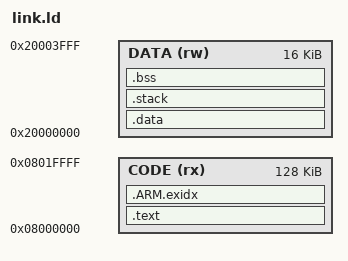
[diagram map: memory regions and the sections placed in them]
/*
 * Linker script for GD32F3x0 with GNU ld
 */

MEMORY
{
    CODE (rx) : ORIGIN = 0x08000000, LENGTH = 128k /* GD32F350RB: 128KB Flash */
    DATA (rw) : ORIGIN = 0x20000000, LENGTH =  16k /* GD32F350RB: 16KB SRAM */
}
ENTRY(Reset_Handler)
_system_stack_size = 0x400;

SECTIONS
{
    .text :
    {
        . = ALIGN(4);
        _stext = .;
        KEEP(*(.isr_vector))            /* Startup code */
        . = ALIGN(4);
        *(.text)
        *(.text.*)
        *(.rodata)
        *(.rodata*)
        *(.glue_7)
        *(.glue_7t)
        *(.gnu.linkonce.t*)

        . = ALIGN(4);
        __fsymtab_start = .;
        KEEP(*(FSymTab))
        __fsymtab_end = .;
        . = ALIGN(4);
        __vsymtab_start = .;
        KEEP(*(VSymTab))
        __vsymtab_end = .;
        . = ALIGN(4);

        . = ALIGN(4);
        __rt_init_start = .;
        KEEP(*(SORT(.rti_fn*)))
        __rt_init_end = .;
        . = ALIGN(4);

        . = ALIGN(4);
        _etext = .;
    } > CODE = 0

    __exidx_start = .;
    .ARM.exidx :
    {
        *(.ARM.exidx* .gnu.linkonce.armexidx.*)

        _sidata = .;
    } > CODE
    __exidx_end = .;

    .data : AT (_sidata)
    {
        . = ALIGN(4);
        _sdata = . ;

        *(.data)
        *(.data.*)
        *(.gnu.linkonce.d*)

        . = ALIGN(4);
        _edata = . ;
    } >DATA

    .stack : 
    {
        . = . + _system_stack_size;
        . = ALIGN(4);
        _estack = .;
    } >DATA

    __bss_start = .;
    .bss :
    {
        . = ALIGN(4);
        _sbss = .;

        *(.bss)
        *(.bss.*)
        *(COMMON)

        . = ALIGN(4);
        _ebss = . ;
        *(.bss.init)
    } > DATA
    __bss_end = .;

    _end = .;

    .stab          0 : { *(.stab) }
    .stabstr       0 : { *(.stabstr) }
    .stab.excl     0 : { *(.stab.excl) }
    .stab.exclstr  0 : { *(.stab.exclstr) }
    .stab.index    0 : { *(.stab.index) }
    .stab.indexstr 0 : { *(.stab.indexstr) }
    .comment       0 : { *(.comment) }

    .debug          0 : { *(.debug) }
    .line           0 : { *(.line) }
    .debug_srcinfo  0 : { *(.debug_srcinfo) }
    .debug_sfnames  0 : { *(.debug_sfnames) }
    .debug_aranges  0 : { *(.debug_aranges) }
    .debug_pubnames 0 : { *(.debug_pubnames) }
    .debug_info     0 : { *(.debug_info .gnu.linkonce.wi.*) }
    .debug_abbrev   0 : { *(.debug_abbrev) }
    .debug_line     0 : { *(.debug_line) }
    .debug_frame    0 : { *(.debug_frame) }
    .debug_str      0 : { *(.debug_str) }
    .debug_loc      0 : { *(.debug_loc) }
    .debug_macinfo  0 : { *(.debug_macinfo) }
    .debug_weaknames 0 : { *(.debug_weaknames) }
    .debug_funcnames 0 : { *(.debug_funcnames) }
    .debug_typenames 0 : { *(.debug_typenames) }
    .debug_varnames  0 : { *(.debug_varnames) }
}
